# sam67_dmpac_wrap0_DMPAC_TOP_CFG_SLV_HTS_S_VBUSP register map
Vendor: Texas Instruments
Peripheral module from a debugger description file (folder J722S).
Registers are 32-bit, read-write, reset 0x0 unless marked. A register's access mark holds for its fields unless they carry their own. Offsets are as the file gives them; lines under a group give offsets from that group; [hi:lo] are bit positions; {n}, {i} and the like mark numbered series; 'fields as' and 'values as' point back to an identical list; <NAME> marks a mode.

## sam67_dmpac_wrap0_DMPAC_TOP_CFG_SLV_HTS_S_VBUSP (part 1 of 2)
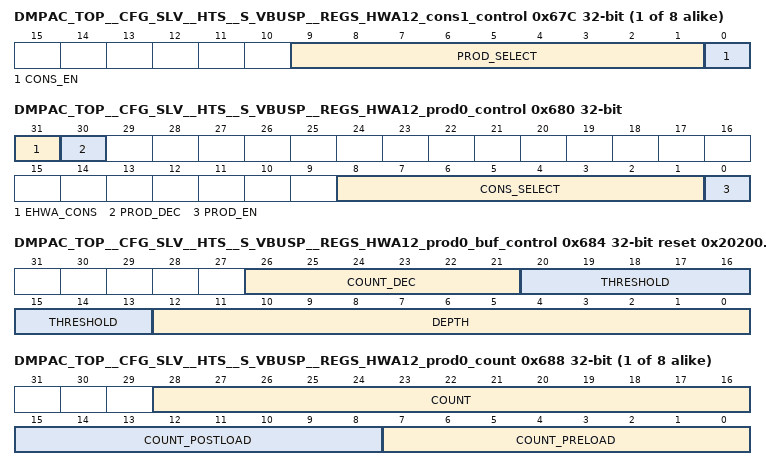
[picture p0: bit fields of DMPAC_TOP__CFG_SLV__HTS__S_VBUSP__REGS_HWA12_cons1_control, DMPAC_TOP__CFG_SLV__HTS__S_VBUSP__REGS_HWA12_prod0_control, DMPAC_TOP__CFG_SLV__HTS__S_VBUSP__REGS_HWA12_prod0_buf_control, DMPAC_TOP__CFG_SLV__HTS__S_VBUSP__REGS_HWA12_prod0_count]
{0x19C+0x68*i} DMPAC_TOP__CFG_SLV__HTS__S_VBUSP__REGS_HWA{i}_cons1_control (i=12..19) — Controlling consumer socket 1 for HWA{i}
  [9:1] PROD_SELECT — producer select for HWA{i} cons socket 1
  [0] CONS_EN — '1' -> Consumer socket 1 enable , '0' Disable
0x680 DMPAC_TOP__CFG_SLV__HTS__S_VBUSP__REGS_HWA12_prod0_control access per field — Controlling producer socket0 for HWA12
  [31] EHWA_CONS rw — '1' -> spare consumer is connected to external host consumer , '0' --> no external host consumer
  [30] PROD_DEC wo — writing '1' decrement prod count value
  [8:1] CONS_SELECT rw — consumer select for HWA12 prod socket 0. Used in decrementing count of producer buffer
  [0] PROD_EN rw — '1' -> Producer socket 0 enable , '0' Disable
{0x1A4+0x68*i} DMPAC_TOP__CFG_SLV__HTS__S_VBUSP__REGS_HWA{i}_prod0_buf_control reset 0x202000 (i=12..19) — Controlling producer socket0 buffer for HWA{i}
  [26:21] COUNT_DEC — Count decrement value for prod count
  [20:13] THRESHOLD — Count threshold to generate pend for consumer
  [12:0] DEPTH — Maximum number of producer buffer count
{0x1A8+0x68*i} DMPAC_TOP__CFG_SLV__HTS__S_VBUSP__REGS_HWA{i}_prod0_count access per field (i=12..19) — Defining count values for pre/post load for generating pend by HWA{i} prod0
  [28:16] COUNT ro — current count value
  [15:8] COUNT_POSTLOAD rw — count postload after producer max thread count reached
  [7:0] COUNT_PRELOAD rw — count preload after scheduler start/init
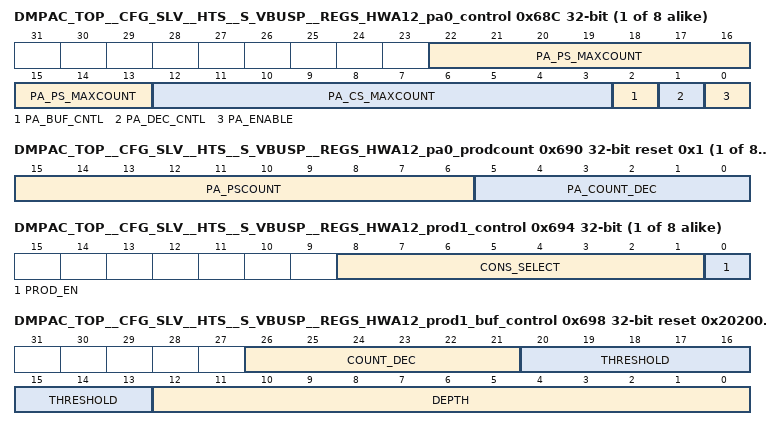
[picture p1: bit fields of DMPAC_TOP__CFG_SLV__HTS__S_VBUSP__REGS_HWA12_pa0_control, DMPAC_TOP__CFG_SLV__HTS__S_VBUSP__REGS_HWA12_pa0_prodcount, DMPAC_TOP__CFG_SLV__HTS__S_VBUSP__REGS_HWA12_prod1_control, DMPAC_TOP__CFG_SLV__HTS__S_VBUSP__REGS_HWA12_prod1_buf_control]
{0x1AC+0x68*i} DMPAC_TOP__CFG_SLV__HTS__S_VBUSP__REGS_HWA{i}_pa0_control (i=12..19) — control register to manage pattern adapter on HWA{i} prod socket0
  [22:13] PA_PS_MAXCOUNT — destination count for pattern adaptation (N), M --> N
  [12:3] PA_CS_MAXCOUNT — source count for pattern adaptation (M), M --> N
  [2] PA_BUF_CNTL — '1' -> Apply threshold, count_preload and count_postload on pattern adapter count (use this only when pa_enable='1') '0' -> Apply threshold, count_preload and count_postload on prod count (same behavior as if no pattern adapter. Note when pa_enable='1' and pa_buf_cntl='0' threshold is not used and ignored)
  [1] PA_DEC_CNTL — '1' -> post pattern adaptation, decrement ps count by count_dec , '0' -> post pattern adaptation, decrement ps count by pa_cs_maxcount
  [0] PA_ENABLE — '1' -> pa enable, '0' -> disable
{0x1B0+0x68*i} DMPAC_TOP__CFG_SLV__HTS__S_VBUSP__REGS_HWA{i}_pa0_prodcount access per field reset 0x1 (i=12..19) — count values for HWA{i} prod socket0
  [15:6] PA_PSCOUNT ro — current count value of pa prod count
  [5:0] PA_COUNT_DEC rw — Decrement count value of pa_prod_count after pattern adapter prod count reaches threshold
{0x1B4+0x68*i} DMPAC_TOP__CFG_SLV__HTS__S_VBUSP__REGS_HWA{i}_prod1_control (i=12..19) — Controlling producer socket1 for HWA{i}
  [8:1] CONS_SELECT — consumer select for HWA{i} prod socket 1. Used in decrementing count of producer buffer
  [0] PROD_EN — '1' -> Producer socket 0 enable , '0' Disable
{0x1B8+0x68*i} DMPAC_TOP__CFG_SLV__HTS__S_VBUSP__REGS_HWA{i}_prod1_buf_control reset 0x202000 (i=12..19) — Controlling producer socket1 buffer for HWA{i}
  fields as DMPAC_TOP__CFG_SLV__HTS__S_VBUSP__REGS_HWA12_prod0_buf_control
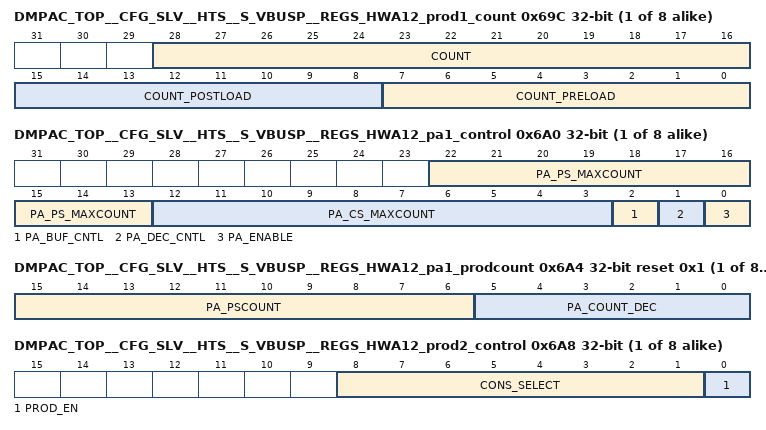
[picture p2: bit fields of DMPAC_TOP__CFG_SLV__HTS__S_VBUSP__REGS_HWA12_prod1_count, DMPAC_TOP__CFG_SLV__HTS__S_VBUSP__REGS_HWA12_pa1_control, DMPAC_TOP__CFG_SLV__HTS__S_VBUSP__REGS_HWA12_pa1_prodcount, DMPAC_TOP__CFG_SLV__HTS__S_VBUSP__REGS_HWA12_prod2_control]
{0x1BC+0x68*i} DMPAC_TOP__CFG_SLV__HTS__S_VBUSP__REGS_HWA{i}_prod1_count access per field (i=12..19) — Defining count values for pre/post load for generating pend by HWA{i} prod1
  fields as DMPAC_TOP__CFG_SLV__HTS__S_VBUSP__REGS_HWA12_prod0_count
{0x1C0+0x68*i} DMPAC_TOP__CFG_SLV__HTS__S_VBUSP__REGS_HWA{i}_pa1_control (i=12..19) — control register to manage pattern adapter on HWA{i} prod socket1
  fields as DMPAC_TOP__CFG_SLV__HTS__S_VBUSP__REGS_HWA12_pa0_control
{0x1C4+0x68*i} DMPAC_TOP__CFG_SLV__HTS__S_VBUSP__REGS_HWA{i}_pa1_prodcount access per field reset 0x1 (i=12..19) — count values for HWA{i} prod socket1
  fields as DMPAC_TOP__CFG_SLV__HTS__S_VBUSP__REGS_HWA12_pa0_prodcount
{0x1C8+0x68*i} DMPAC_TOP__CFG_SLV__HTS__S_VBUSP__REGS_HWA{i}_prod2_control (i=12..19) — Controlling producer socket2 for HWA{i}
  [8:1] CONS_SELECT — consumer select for HWA{i} prod socket 2. Used in decrementing count of producer buffer
  [0] PROD_EN — '1' -> Producer socket 0 enable , '0' Disable
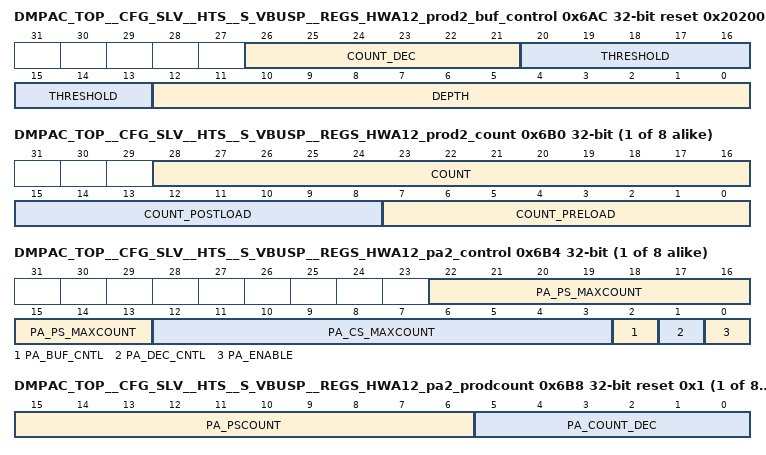
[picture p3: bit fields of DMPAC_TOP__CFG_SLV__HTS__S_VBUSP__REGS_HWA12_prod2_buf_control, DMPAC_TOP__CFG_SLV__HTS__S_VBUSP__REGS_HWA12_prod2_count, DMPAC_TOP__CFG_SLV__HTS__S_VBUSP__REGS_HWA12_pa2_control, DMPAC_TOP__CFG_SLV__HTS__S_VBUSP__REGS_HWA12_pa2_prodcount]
{0x1CC+0x68*i} DMPAC_TOP__CFG_SLV__HTS__S_VBUSP__REGS_HWA{i}_prod2_buf_control reset 0x202000 (i=12..19) — Controlling producer socket2 buffer for HWA{i}
  fields as DMPAC_TOP__CFG_SLV__HTS__S_VBUSP__REGS_HWA12_prod0_buf_control
{0x1D0+0x68*i} DMPAC_TOP__CFG_SLV__HTS__S_VBUSP__REGS_HWA{i}_prod2_count access per field (i=12..19) — Defining count values for pre/post load for generating pend by HWA{i} prod2
  fields as DMPAC_TOP__CFG_SLV__HTS__S_VBUSP__REGS_HWA12_prod0_count
{0x1D4+0x68*i} DMPAC_TOP__CFG_SLV__HTS__S_VBUSP__REGS_HWA{i}_pa2_control (i=12..19) — control register to manage pattern adapter on HWA{i} prod socket2
  fields as DMPAC_TOP__CFG_SLV__HTS__S_VBUSP__REGS_HWA12_pa0_control
{0x1D8+0x68*i} DMPAC_TOP__CFG_SLV__HTS__S_VBUSP__REGS_HWA{i}_pa2_prodcount access per field reset 0x1 (i=12..19) — count values for HWA{i} prod socket2
  fields as DMPAC_TOP__CFG_SLV__HTS__S_VBUSP__REGS_HWA12_pa0_prodcount
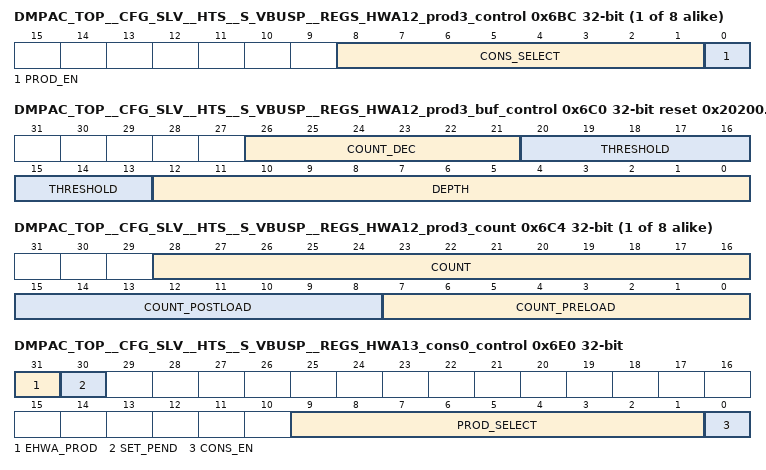
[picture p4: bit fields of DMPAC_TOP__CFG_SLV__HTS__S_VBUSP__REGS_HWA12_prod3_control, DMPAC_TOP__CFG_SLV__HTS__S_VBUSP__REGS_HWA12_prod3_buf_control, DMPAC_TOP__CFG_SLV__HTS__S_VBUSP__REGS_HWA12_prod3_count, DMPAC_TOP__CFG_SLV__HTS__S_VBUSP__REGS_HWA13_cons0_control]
{0x1DC+0x68*i} DMPAC_TOP__CFG_SLV__HTS__S_VBUSP__REGS_HWA{i}_prod3_control (i=12..19) — Controlling producer socket3 for HWA{i}
  [8:1] CONS_SELECT — consumer select for HWA{i} prod socket 3. Used in decrementing count of producer buffer
  [0] PROD_EN — '1' -> Producer socket 0 enable , '0' Disable
{0x1E0+0x68*i} DMPAC_TOP__CFG_SLV__HTS__S_VBUSP__REGS_HWA{i}_prod3_buf_control reset 0x202000 (i=12..19) — Controlling producer socket3 buffer for HWA{i}
  fields as DMPAC_TOP__CFG_SLV__HTS__S_VBUSP__REGS_HWA12_prod0_buf_control
{0x1E4+0x68*i} DMPAC_TOP__CFG_SLV__HTS__S_VBUSP__REGS_HWA{i}_prod3_count access per field (i=12..19) — Defining count values for pre/post load for generating pend by HWA{i} prod3
  fields as DMPAC_TOP__CFG_SLV__HTS__S_VBUSP__REGS_HWA12_prod0_count
0x6E0 DMPAC_TOP__CFG_SLV__HTS__S_VBUSP__REGS_HWA13_cons0_control access per field — Controlling consumer socket 0 for HWA13
  [31] EHWA_PROD rw — '1' -> spare consumer is connected to external host producer , '0' --> no external host producer
  [30] SET_PEND wo — writing '1' sets pend on consumer socket
  [9:1] PROD_SELECT rw — producer select for HWA13 cons socket 0
  [0] CONS_EN rw — '1' -> Consumer socket 0 enable , '0' Disable
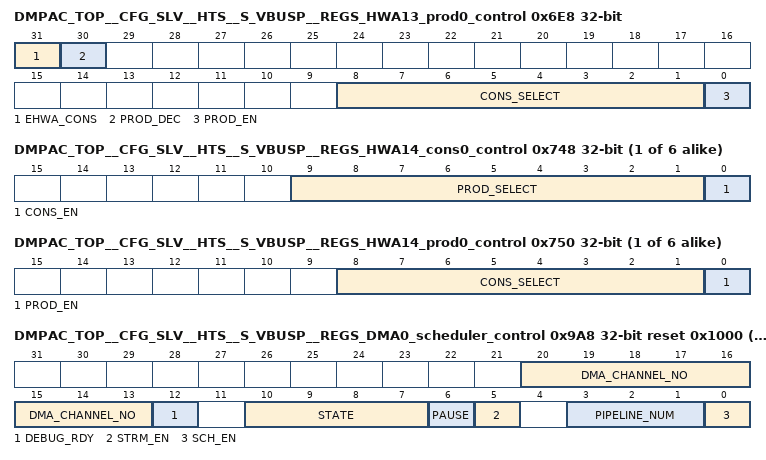
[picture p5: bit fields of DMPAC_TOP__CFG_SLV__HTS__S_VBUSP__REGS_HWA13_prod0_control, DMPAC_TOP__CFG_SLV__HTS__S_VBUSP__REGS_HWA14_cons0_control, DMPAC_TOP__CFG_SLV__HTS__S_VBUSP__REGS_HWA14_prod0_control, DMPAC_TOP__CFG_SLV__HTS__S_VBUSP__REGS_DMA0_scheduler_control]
0x6E8 DMPAC_TOP__CFG_SLV__HTS__S_VBUSP__REGS_HWA13_prod0_control access per field — Controlling producer socket0 for HWA13
  [31] EHWA_CONS rw — '1' -> spare consumer is connected to external host consumer , '0' --> no external host consumer
  [30] PROD_DEC wo — writing '1' decrement prod count value
  [8:1] CONS_SELECT rw — consumer select for HWA13 prod socket 0. Used in decrementing count of producer buffer
  [0] PROD_EN rw — '1' -> Producer socket 0 enable , '0' Disable
{0x198+0x68*i} DMPAC_TOP__CFG_SLV__HTS__S_VBUSP__REGS_HWA{i}_cons0_control (i=14..19) — Controlling consumer socket 0 for HWA{i}
  [9:1] PROD_SELECT — producer select for HWA{i} cons socket 0
  [0] CONS_EN — '1' -> Consumer socket 0 enable , '0' Disable
{0x1A0+0x68*i} DMPAC_TOP__CFG_SLV__HTS__S_VBUSP__REGS_HWA{i}_prod0_control (i=14..19) — Controlling producer socket0 for HWA{i}
  [8:1] CONS_SELECT — consumer select for HWA{i} prod socket 0. Used in decrementing count of producer buffer
  [0] PROD_EN — '1' -> Producer socket 0 enable , '0' Disable
{0x9A8+0x1C*i} DMPAC_TOP__CFG_SLV__HTS__S_VBUSP__REGS_DMA{i}_scheduler_control access per field reset 0x1000 (i=0..4) — Scheduler Control Register
  [20:13] DMA_CHANNEL_NO rw — DMA channel number for thread scheduler for DMA{i}
  [12] DEBUG_RDY rw — '0' -> DMA{i} Scheduler resources must not be read during halted state. '1'-> DMA{i} Scheduler resources are readable during halted state
  [10:7] STATE ro — Current state of DMA{i} Scheduler
  [6] PAUSE rw — '1' -> pause/suspend scheduler , '0' -> resume scheduler
  [5] STRM_EN rw — '1' -> Streaming input enable, '0' No streaming input
  [3:1] PIPELINE_NUM rw — Pipeline Number of DMA{i} Scheduler
  [0] SCH_EN rw — scheduler enable; write '1' to enable scheduler
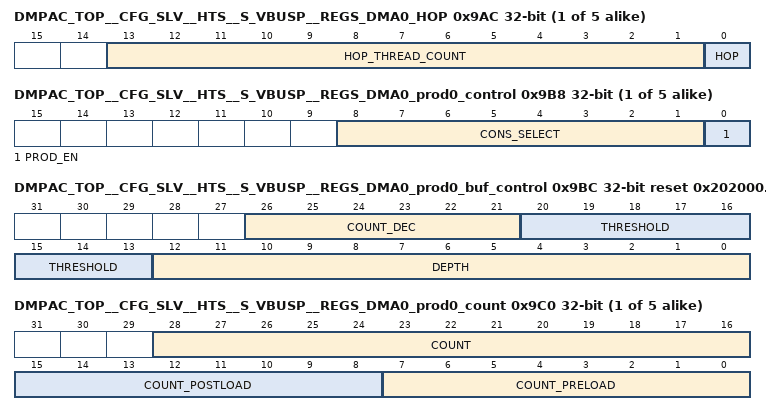
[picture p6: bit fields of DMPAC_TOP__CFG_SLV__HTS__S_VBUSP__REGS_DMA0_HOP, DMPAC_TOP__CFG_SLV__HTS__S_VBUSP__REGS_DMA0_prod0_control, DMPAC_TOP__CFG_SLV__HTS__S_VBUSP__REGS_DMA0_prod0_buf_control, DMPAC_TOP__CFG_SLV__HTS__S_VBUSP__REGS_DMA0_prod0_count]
{0x9AC+0x1C*i} DMPAC_TOP__CFG_SLV__HTS__S_VBUSP__REGS_DMA{i}_HOP (i=0..4) — Scheduler HOP Control Register. Help in detecting eop within scheduler. Once configured, it counts task/channel starts and stops issuing further starts. Specifically useful for Head of pipe dma scheduler .
  [13:1] HOP_THREAD_COUNT — Number of Task count for Head of pipe
  [0] HOP — '1' -> Head of Pipe producer Sch , '0' -> No hop
{0x9B8+0x1C*i} DMPAC_TOP__CFG_SLV__HTS__S_VBUSP__REGS_DMA{i}_prod0_control (i=0..4) — Controlling producer socket0 for DMA{i}
  [8:1] CONS_SELECT — consumer select for DMA{i} prod socket 0. Used in decrementing count of producer buffer
  [0] PROD_EN — '1' -> Producer socket 0 enable , '0' Disable
{0x9BC+0x1C*i} DMPAC_TOP__CFG_SLV__HTS__S_VBUSP__REGS_DMA{i}_prod0_buf_control reset 0x202000 (i=0..4) — Controlling producer socket0 buffer for DMA{i}
  fields as DMPAC_TOP__CFG_SLV__HTS__S_VBUSP__REGS_HWA12_prod0_buf_control
{0x9C0+0x1C*i} DMPAC_TOP__CFG_SLV__HTS__S_VBUSP__REGS_DMA{i}_prod0_count access per field (i=0..4) — Defining count values for pre/post load for generating pend by DMA{i} prod0
  fields as DMPAC_TOP__CFG_SLV__HTS__S_VBUSP__REGS_HWA12_prod0_count
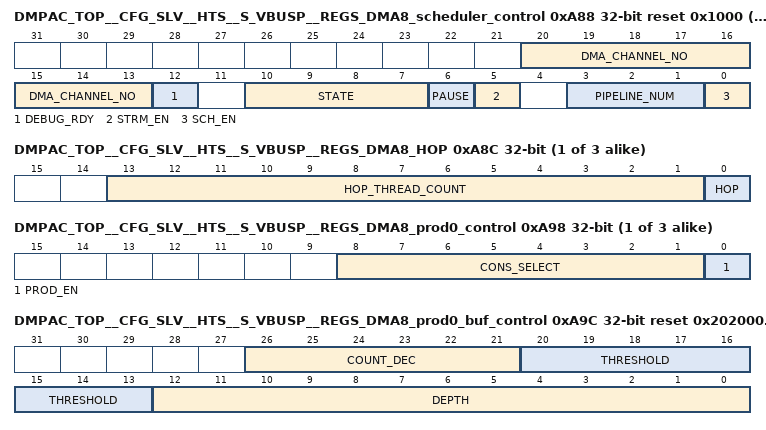
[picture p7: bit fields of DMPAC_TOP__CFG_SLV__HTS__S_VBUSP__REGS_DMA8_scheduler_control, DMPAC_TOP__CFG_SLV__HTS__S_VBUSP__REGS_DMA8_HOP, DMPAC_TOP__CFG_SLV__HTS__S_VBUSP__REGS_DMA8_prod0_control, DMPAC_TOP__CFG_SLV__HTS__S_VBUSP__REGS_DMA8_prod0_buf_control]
{0x968+0x24*i} DMPAC_TOP__CFG_SLV__HTS__S_VBUSP__REGS_DMA{i}_scheduler_control access per field reset 0x1000 (i=8..10) — Scheduler Control Register
  fields as DMPAC_TOP__CFG_SLV__HTS__S_VBUSP__REGS_DMA0_scheduler_control
{0x96C+0x24*i} DMPAC_TOP__CFG_SLV__HTS__S_VBUSP__REGS_DMA{i}_HOP (i=8..10) — Scheduler HOP Control Register. Help in detecting eop within scheduler. Once configured, it counts task/channel starts and stops issuing further starts. Specifically useful for Head of pipe dma scheduler .
  fields as DMPAC_TOP__CFG_SLV__HTS__S_VBUSP__REGS_DMA0_HOP
{0x978+0x24*i} DMPAC_TOP__CFG_SLV__HTS__S_VBUSP__REGS_DMA{i}_prod0_control (i=8..10) — Controlling producer socket0 for DMA{i}
  fields as DMPAC_TOP__CFG_SLV__HTS__S_VBUSP__REGS_DMA0_prod0_control
{0x97C+0x24*i} DMPAC_TOP__CFG_SLV__HTS__S_VBUSP__REGS_DMA{i}_prod0_buf_control reset 0x202000 (i=8..10) — Controlling producer socket0 buffer for DMA{i}
  fields as DMPAC_TOP__CFG_SLV__HTS__S_VBUSP__REGS_HWA12_prod0_buf_control
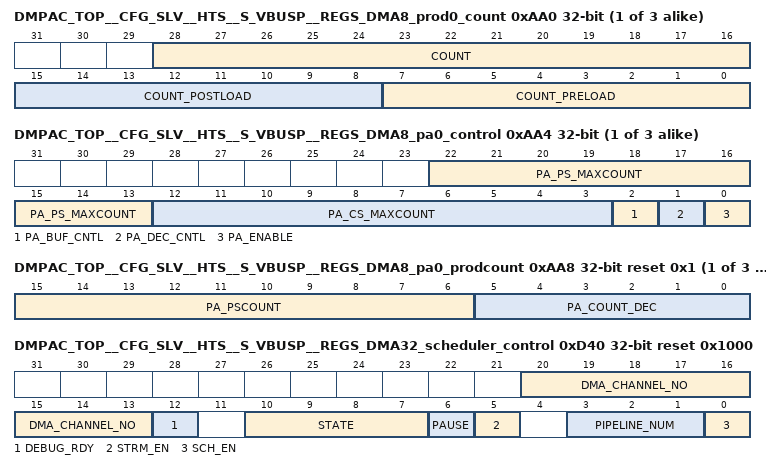
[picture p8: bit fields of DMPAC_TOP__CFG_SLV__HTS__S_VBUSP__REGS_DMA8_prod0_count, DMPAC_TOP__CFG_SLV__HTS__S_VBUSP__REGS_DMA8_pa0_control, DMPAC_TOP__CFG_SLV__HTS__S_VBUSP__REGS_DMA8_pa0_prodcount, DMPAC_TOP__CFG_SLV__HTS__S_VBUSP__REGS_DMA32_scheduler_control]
{0x980+0x24*i} DMPAC_TOP__CFG_SLV__HTS__S_VBUSP__REGS_DMA{i}_prod0_count access per field (i=8..10) — Defining count values for pre/post load for generating pend by DMA{i} prod0
  fields as DMPAC_TOP__CFG_SLV__HTS__S_VBUSP__REGS_HWA12_prod0_count
{0x984+0x24*i} DMPAC_TOP__CFG_SLV__HTS__S_VBUSP__REGS_DMA{i}_pa0_control (i=8..10) — control register to manage pattern adapter on DMA{i} prod socket0
  fields as DMPAC_TOP__CFG_SLV__HTS__S_VBUSP__REGS_HWA12_pa0_control
{0x988+0x24*i} DMPAC_TOP__CFG_SLV__HTS__S_VBUSP__REGS_DMA{i}_pa0_prodcount access per field reset 0x1 (i=8..10) — count values for HWA{i} prod socket0
  fields as DMPAC_TOP__CFG_SLV__HTS__S_VBUSP__REGS_HWA12_pa0_prodcount
0xD40 DMPAC_TOP__CFG_SLV__HTS__S_VBUSP__REGS_DMA32_scheduler_control access per field reset 0x1000 — Scheduler Control Register
  [20:13] DMA_CHANNEL_NO rw — DMA channel number for thread scheduler for DMA32
  [12] DEBUG_RDY rw — '0' -> DMA32 Scheduler resources must not be read during halted state. '1'-> DMA32 Scheduler resources are readable during halted state
  [10:7] STATE ro — Current state of DMA32 Scheduler
  [6] PAUSE rw — '1' -> pause/suspend scheduler , '0' -> resume scheduler
  [5] STRM_EN rw — '1' -> Streaming input enable, '0' No streaming input
  [3:1] PIPELINE_NUM rw — Pipeline Number of DMA32 Scheduler
  [0] SCH_EN rw — scheduler enable; write '1' to enable scheduler
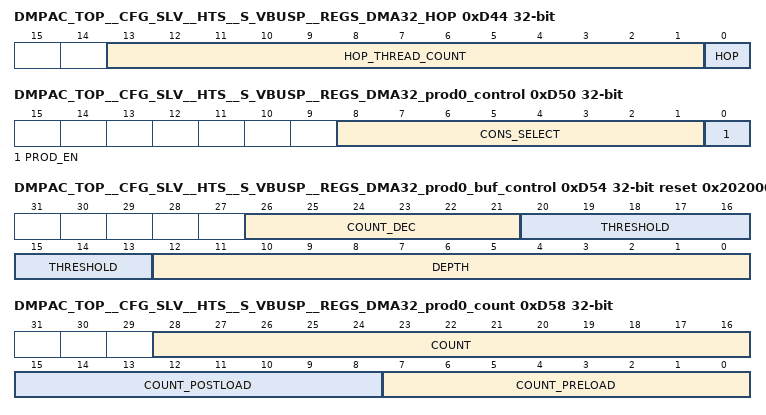
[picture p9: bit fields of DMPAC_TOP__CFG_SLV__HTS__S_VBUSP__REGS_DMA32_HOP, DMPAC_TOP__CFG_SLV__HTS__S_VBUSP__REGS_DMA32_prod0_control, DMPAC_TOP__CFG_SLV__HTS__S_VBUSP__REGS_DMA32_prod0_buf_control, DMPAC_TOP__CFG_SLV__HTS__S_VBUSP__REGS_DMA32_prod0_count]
0xD44 DMPAC_TOP__CFG_SLV__HTS__S_VBUSP__REGS_DMA32_HOP — Scheduler HOP Control Register. Help in detecting eop within scheduler. Once configured, it counts task/channel starts and stops issuing further starts. Specifically useful for Head of pipe dma scheduler .
  fields as DMPAC_TOP__CFG_SLV__HTS__S_VBUSP__REGS_DMA0_HOP
0xD50 DMPAC_TOP__CFG_SLV__HTS__S_VBUSP__REGS_DMA32_prod0_control — Controlling producer socket0 for DMA32
  [8:1] CONS_SELECT — consumer select for DMA32 prod socket 0. Used in decrementing count of producer buffer
  [0] PROD_EN — '1' -> Producer socket 0 enable , '0' Disable
0xD54 DMPAC_TOP__CFG_SLV__HTS__S_VBUSP__REGS_DMA32_prod0_buf_control reset 0x202000 — Controlling producer socket0 buffer for DMA32
  fields as DMPAC_TOP__CFG_SLV__HTS__S_VBUSP__REGS_HWA12_prod0_buf_control
0xD58 DMPAC_TOP__CFG_SLV__HTS__S_VBUSP__REGS_DMA32_prod0_count access per field — Defining count values for pre/post load for generating pend by DMA32 prod0
  fields as DMPAC_TOP__CFG_SLV__HTS__S_VBUSP__REGS_HWA12_prod0_count
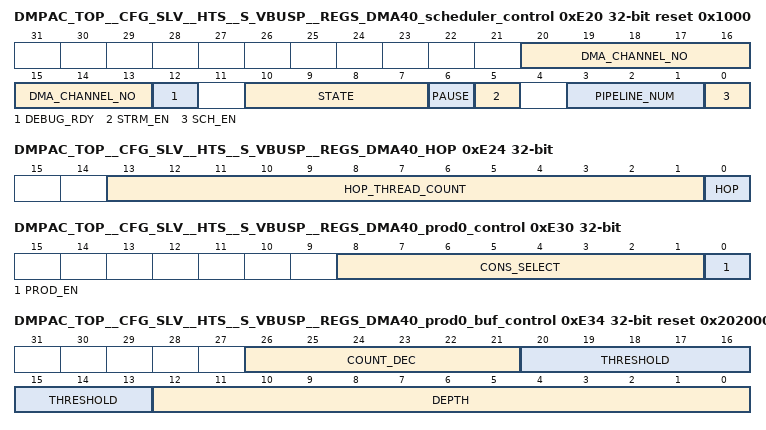
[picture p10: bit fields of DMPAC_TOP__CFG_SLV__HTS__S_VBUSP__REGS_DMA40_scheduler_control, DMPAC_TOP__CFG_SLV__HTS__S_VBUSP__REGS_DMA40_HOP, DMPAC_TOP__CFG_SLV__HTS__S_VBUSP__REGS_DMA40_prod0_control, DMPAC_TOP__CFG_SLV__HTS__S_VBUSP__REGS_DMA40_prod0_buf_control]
0xE20 DMPAC_TOP__CFG_SLV__HTS__S_VBUSP__REGS_DMA40_scheduler_control access per field reset 0x1000 — Scheduler Control Register
  [20:13] DMA_CHANNEL_NO rw — DMA channel number for thread scheduler for DMA40
  [12] DEBUG_RDY rw — '0' -> DMA40 Scheduler resources must not be read during halted state. '1'-> DMA40 Scheduler resources are readable during halted state
  [10:7] STATE ro — Current state of DMA40 Scheduler
  [6] PAUSE rw — '1' -> pause/suspend scheduler , '0' -> resume scheduler
  [5] STRM_EN rw — '1' -> Streaming input enable, '0' No streaming input
  [3:1] PIPELINE_NUM rw — Pipeline Number of DMA40 Scheduler
  [0] SCH_EN rw — scheduler enable; write '1' to enable scheduler
0xE24 DMPAC_TOP__CFG_SLV__HTS__S_VBUSP__REGS_DMA40_HOP — Scheduler HOP Control Register. Help in detecting eop within scheduler. Once configured, it counts task/channel starts and stops issuing further starts. Specifically useful for Head of pipe dma scheduler .
  fields as DMPAC_TOP__CFG_SLV__HTS__S_VBUSP__REGS_DMA0_HOP
0xE30 DMPAC_TOP__CFG_SLV__HTS__S_VBUSP__REGS_DMA40_prod0_control — Controlling producer socket0 for DMA40
  [8:1] CONS_SELECT — consumer select for DMA40 prod socket 0. Used in decrementing count of producer buffer
  [0] PROD_EN — '1' -> Producer socket 0 enable , '0' Disable
0xE34 DMPAC_TOP__CFG_SLV__HTS__S_VBUSP__REGS_DMA40_prod0_buf_control reset 0x202000 — Controlling producer socket0 buffer for DMA40
  fields as DMPAC_TOP__CFG_SLV__HTS__S_VBUSP__REGS_HWA12_prod0_buf_control
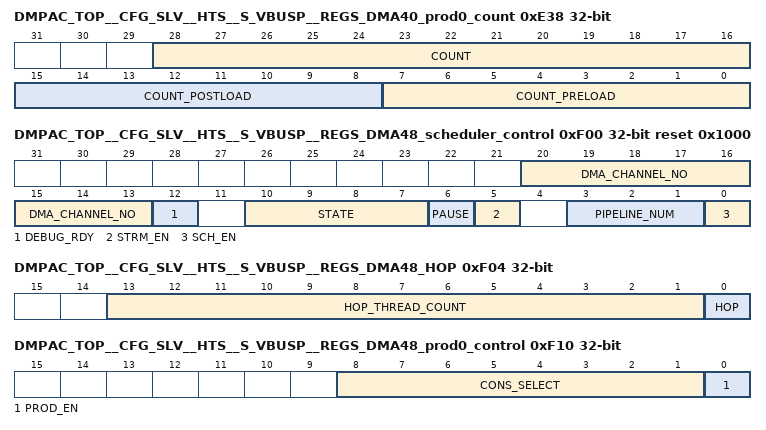
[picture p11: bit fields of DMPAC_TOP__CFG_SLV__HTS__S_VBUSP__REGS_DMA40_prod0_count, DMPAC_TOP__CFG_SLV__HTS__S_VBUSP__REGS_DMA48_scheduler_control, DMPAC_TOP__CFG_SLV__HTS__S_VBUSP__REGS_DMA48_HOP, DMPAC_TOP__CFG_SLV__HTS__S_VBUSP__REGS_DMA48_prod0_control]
0xE38 DMPAC_TOP__CFG_SLV__HTS__S_VBUSP__REGS_DMA40_prod0_count access per field — Defining count values for pre/post load for generating pend by DMA40 prod0
  fields as DMPAC_TOP__CFG_SLV__HTS__S_VBUSP__REGS_HWA12_prod0_count
0xF00 DMPAC_TOP__CFG_SLV__HTS__S_VBUSP__REGS_DMA48_scheduler_control access per field reset 0x1000 — Scheduler Control Register
  [20:13] DMA_CHANNEL_NO rw — DMA channel number for thread scheduler for DMA48
  [12] DEBUG_RDY rw — '0' -> DMA48 Scheduler resources must not be read during halted state. '1'-> DMA48 Scheduler resources are readable during halted state
  [10:7] STATE ro — Current state of DMA48 Scheduler
  [6] PAUSE rw — '1' -> pause/suspend scheduler , '0' -> resume scheduler
  [5] STRM_EN rw — '1' -> Streaming input enable, '0' No streaming input
  [3:1] PIPELINE_NUM rw — Pipeline Number of DMA48 Scheduler
  [0] SCH_EN rw — scheduler enable; write '1' to enable scheduler
0xF04 DMPAC_TOP__CFG_SLV__HTS__S_VBUSP__REGS_DMA48_HOP — Scheduler HOP Control Register. Help in detecting eop within scheduler. Once configured, it counts task/channel starts and stops issuing further starts. Specifically useful for Head of pipe dma scheduler .
  fields as DMPAC_TOP__CFG_SLV__HTS__S_VBUSP__REGS_DMA0_HOP
0xF10 DMPAC_TOP__CFG_SLV__HTS__S_VBUSP__REGS_DMA48_prod0_control — Controlling producer socket0 for DMA48
  [8:1] CONS_SELECT — consumer select for DMA48 prod socket 0. Used in decrementing count of producer buffer
  [0] PROD_EN — '1' -> Producer socket 0 enable , '0' Disable
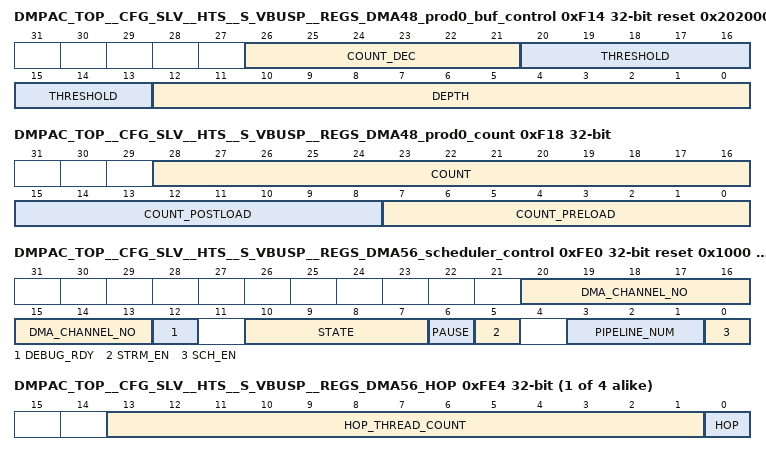
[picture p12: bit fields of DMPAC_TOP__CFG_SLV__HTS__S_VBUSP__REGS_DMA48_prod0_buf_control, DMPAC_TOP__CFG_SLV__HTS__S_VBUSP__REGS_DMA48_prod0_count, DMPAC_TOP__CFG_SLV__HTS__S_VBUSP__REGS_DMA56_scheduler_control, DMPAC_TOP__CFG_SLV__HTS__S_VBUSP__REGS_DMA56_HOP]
0xF14 DMPAC_TOP__CFG_SLV__HTS__S_VBUSP__REGS_DMA48_prod0_buf_control reset 0x202000 — Controlling producer socket0 buffer for DMA48
  fields as DMPAC_TOP__CFG_SLV__HTS__S_VBUSP__REGS_HWA12_prod0_buf_control
0xF18 DMPAC_TOP__CFG_SLV__HTS__S_VBUSP__REGS_DMA48_prod0_count access per field — Defining count values for pre/post load for generating pend by DMA48 prod0
  fields as DMPAC_TOP__CFG_SLV__HTS__S_VBUSP__REGS_HWA12_prod0_count
{0x9C0+0x1C*i} DMPAC_TOP__CFG_SLV__HTS__S_VBUSP__REGS_DMA{i}_scheduler_control access per field reset 0x1000 (i=56..59) — Scheduler Control Register
  fields as DMPAC_TOP__CFG_SLV__HTS__S_VBUSP__REGS_DMA0_scheduler_control
{0x9C4+0x1C*i} DMPAC_TOP__CFG_SLV__HTS__S_VBUSP__REGS_DMA{i}_HOP (i=56..59) — Scheduler HOP Control Register. Help in detecting eop within scheduler. Once configured, it counts task/channel starts and stops issuing further starts. Specifically useful for Head of pipe dma scheduler .
  fields as DMPAC_TOP__CFG_SLV__HTS__S_VBUSP__REGS_DMA0_HOP
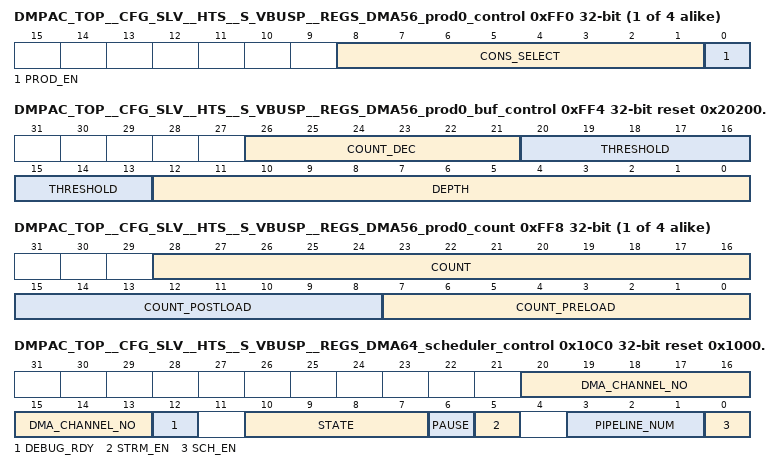
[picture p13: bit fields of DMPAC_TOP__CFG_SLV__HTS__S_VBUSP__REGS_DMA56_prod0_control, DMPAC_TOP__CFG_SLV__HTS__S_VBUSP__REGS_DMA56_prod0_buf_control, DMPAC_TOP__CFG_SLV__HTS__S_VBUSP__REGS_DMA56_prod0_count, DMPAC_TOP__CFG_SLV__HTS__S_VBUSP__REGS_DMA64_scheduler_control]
{0x9D0+0x1C*i} DMPAC_TOP__CFG_SLV__HTS__S_VBUSP__REGS_DMA{i}_prod0_control (i=56..59) — Controlling producer socket0 for DMA{i}
  fields as DMPAC_TOP__CFG_SLV__HTS__S_VBUSP__REGS_DMA0_prod0_control
{0x9D4+0x1C*i} DMPAC_TOP__CFG_SLV__HTS__S_VBUSP__REGS_DMA{i}_prod0_buf_control reset 0x202000 (i=56..59) — Controlling producer socket0 buffer for DMA{i}
  fields as DMPAC_TOP__CFG_SLV__HTS__S_VBUSP__REGS_HWA12_prod0_buf_control
{0x9D8+0x1C*i} DMPAC_TOP__CFG_SLV__HTS__S_VBUSP__REGS_DMA{i}_prod0_count access per field (i=56..59) — Defining count values for pre/post load for generating pend by DMA{i} prod0
  fields as DMPAC_TOP__CFG_SLV__HTS__S_VBUSP__REGS_HWA12_prod0_count
{0x9C0+0x1C*i} DMPAC_TOP__CFG_SLV__HTS__S_VBUSP__REGS_DMA{i}_scheduler_control access per field reset 0x1000 (i=64..67) — Scheduler Control Register
  fields as DMPAC_TOP__CFG_SLV__HTS__S_VBUSP__REGS_DMA0_scheduler_control
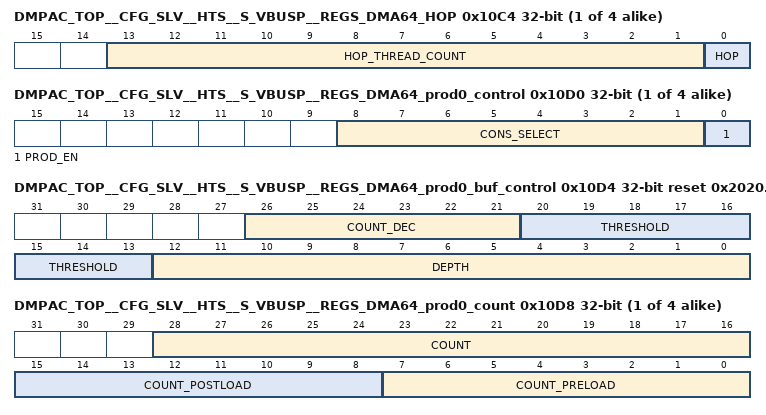
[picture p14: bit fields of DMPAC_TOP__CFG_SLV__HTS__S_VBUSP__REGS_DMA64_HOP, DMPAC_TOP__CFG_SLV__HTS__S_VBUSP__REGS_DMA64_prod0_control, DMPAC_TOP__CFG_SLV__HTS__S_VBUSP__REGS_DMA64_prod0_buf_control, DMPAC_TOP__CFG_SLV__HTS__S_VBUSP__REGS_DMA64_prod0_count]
{0x9C4+0x1C*i} DMPAC_TOP__CFG_SLV__HTS__S_VBUSP__REGS_DMA{i}_HOP (i=64..67) — Scheduler HOP Control Register. Help in detecting eop within scheduler. Once configured, it counts task/channel starts and stops issuing further starts. Specifically useful for Head of pipe dma scheduler .
  fields as DMPAC_TOP__CFG_SLV__HTS__S_VBUSP__REGS_DMA0_HOP
{0x9D0+0x1C*i} DMPAC_TOP__CFG_SLV__HTS__S_VBUSP__REGS_DMA{i}_prod0_control (i=64..67) — Controlling producer socket0 for DMA{i}
  fields as DMPAC_TOP__CFG_SLV__HTS__S_VBUSP__REGS_DMA0_prod0_control
{0x9D4+0x1C*i} DMPAC_TOP__CFG_SLV__HTS__S_VBUSP__REGS_DMA{i}_prod0_buf_control reset 0x202000 (i=64..67) — Controlling producer socket0 buffer for DMA{i}
  fields as DMPAC_TOP__CFG_SLV__HTS__S_VBUSP__REGS_HWA12_prod0_buf_control
{0x9D8+0x1C*i} DMPAC_TOP__CFG_SLV__HTS__S_VBUSP__REGS_DMA{i}_prod0_count access per field (i=64..67) — Defining count values for pre/post load for generating pend by DMA{i} prod0
  fields as DMPAC_TOP__CFG_SLV__HTS__S_VBUSP__REGS_HWA12_prod0_count
{0xEF4+0x14*i} DMPAC_TOP__CFG_SLV__HTS__S_VBUSP__REGS_DMA{i}_scheduler_control access per field reset 0x1000 (i=240..245) — Scheduler Control Register
  fields as DMPAC_TOP__CFG_SLV__HTS__S_VBUSP__REGS_DMA0_scheduler_control
{0xF04+0x14*i} DMPAC_TOP__CFG_SLV__HTS__S_VBUSP__REGS_DMA{i}_cons0_control (i=240..245) — Controlling consumer socket 0 for DMA{i}
  [9:1] PROD_SELECT — producer select for DMA{i} cons socket 0
  [0] CONS_EN — '1' -> Consumer socket 0 enable , '0' Disable
{0xE2C+0x14*i} DMPAC_TOP__CFG_SLV__HTS__S_VBUSP__REGS_DMA{i}_scheduler_control access per field reset 0x1000 (i=256..261) — Scheduler Control Register
  fields as DMPAC_TOP__CFG_SLV__HTS__S_VBUSP__REGS_DMA0_scheduler_control
{0xE3C+0x14*i} DMPAC_TOP__CFG_SLV__HTS__S_VBUSP__REGS_DMA{i}_cons0_control (i=256..261) — Controlling consumer socket 0 for DMA{i}
  fields as DMPAC_TOP__CFG_SLV__HTS__S_VBUSP__REGS_DMA240_cons0_control
{0xD64+0x14*i} DMPAC_TOP__CFG_SLV__HTS__S_VBUSP__REGS_DMA{i}_scheduler_control access per field reset 0x1000 (i=272..275) — Scheduler Control Register
  fields as DMPAC_TOP__CFG_SLV__HTS__S_VBUSP__REGS_DMA0_scheduler_control
{0xD74+0x14*i} DMPAC_TOP__CFG_SLV__HTS__S_VBUSP__REGS_DMA{i}_cons0_control (i=272..275) — Controlling consumer socket 0 for DMA{i}
  fields as DMPAC_TOP__CFG_SLV__HTS__S_VBUSP__REGS_DMA240_cons0_control
{0xC74+0x14*i} DMPAC_TOP__CFG_SLV__HTS__S_VBUSP__REGS_DMA{i}_scheduler_control access per field reset 0x1000 (i=288..291) — Scheduler Control Register
  fields as DMPAC_TOP__CFG_SLV__HTS__S_VBUSP__REGS_DMA0_scheduler_control
{0xC84+0x14*i} DMPAC_TOP__CFG_SLV__HTS__S_VBUSP__REGS_DMA{i}_cons0_control (i=288..291) — Controlling consumer socket 0 for DMA{i}
  fields as DMPAC_TOP__CFG_SLV__HTS__S_VBUSP__REGS_DMA240_cons0_control
{0xB84+0x14*i} DMPAC_TOP__CFG_SLV__HTS__S_VBUSP__REGS_DMA{i}_scheduler_control access per field reset 0x1000 (i=304..313) — Scheduler Control Register
  fields as DMPAC_TOP__CFG_SLV__HTS__S_VBUSP__REGS_DMA0_scheduler_control
{0xB94+0x14*i} DMPAC_TOP__CFG_SLV__HTS__S_VBUSP__REGS_DMA{i}_cons0_control (i=304..313) — Controlling consumer socket 0 for DMA{i}
  fields as DMPAC_TOP__CFG_SLV__HTS__S_VBUSP__REGS_DMA240_cons0_control
0x240C DMPAC_TOP__CFG_SLV__HTS__S_VBUSP__REGS_DMA336_scheduler_control access per field reset 0x1000 — Scheduler Control Register
  [20:13] DMA_CHANNEL_NO rw — DMA channel number for thread scheduler for DMA336
  [12] DEBUG_RDY rw — '0' -> DMA336 Scheduler resources must not be read during halted state. '1'-> DMA336 Scheduler resources are readable during halted state
  [10:7] STATE ro — Current state of DMA336 Scheduler
  [6] PAUSE rw — '1' -> pause/suspend scheduler , '0' -> resume scheduler
  [5] STRM_EN rw — '1' -> Streaming input enable, '0' No streaming input
  [3:1] PIPELINE_NUM rw — Pipeline Number of DMA336 Scheduler
  [0] SCH_EN rw — scheduler enable; write '1' to enable scheduler
0x241C DMPAC_TOP__CFG_SLV__HTS__S_VBUSP__REGS_DMA336_cons0_control — Controlling consumer socket 0 for DMA336
  [9:1] PROD_SELECT — producer select for DMA336 cons socket 0
  [0] CONS_EN — '1' -> Consumer socket 0 enable , '0' Disable
{0x8A0+0x14*i} DMPAC_TOP__CFG_SLV__HTS__S_VBUSP__REGS_DMA{i}_scheduler_control access per field reset 0x1000 (i=352..355) — Scheduler Control Register
  fields as DMPAC_TOP__CFG_SLV__HTS__S_VBUSP__REGS_DMA0_scheduler_control
{0x8B0+0x14*i} DMPAC_TOP__CFG_SLV__HTS__S_VBUSP__REGS_DMA{i}_cons0_control (i=352..355) — Controlling consumer socket 0 for DMA{i}
  fields as DMPAC_TOP__CFG_SLV__HTS__S_VBUSP__REGS_DMA240_cons0_control
{0x7B0+0x14*i} DMPAC_TOP__CFG_SLV__HTS__S_VBUSP__REGS_DMA{i}_scheduler_control access per field reset 0x1000 (i=368..371) — Scheduler Control Register
  fields as DMPAC_TOP__CFG_SLV__HTS__S_VBUSP__REGS_DMA0_scheduler_control
{0x7C0+0x14*i} DMPAC_TOP__CFG_SLV__HTS__S_VBUSP__REGS_DMA{i}_cons0_control (i=368..371) — Controlling consumer socket 0 for DMA{i}
  fields as DMPAC_TOP__CFG_SLV__HTS__S_VBUSP__REGS_DMA240_cons0_control
0x2650 DMPAC_TOP__CFG_SLV__HTS__S_VBUSP__REGS_pipe_dbg_cntl access per field — Pipeline Debug Control register is used by debug software to control pipeline debug behavior
  [19:17] DEBUG_STATE ro — Current state of Debug activity
  [16] ABORT_DEBUG wo — '1' -> Abort Debug activity on debug enabled pipelines, '0' no impact
  [6] PIPE_DBG_DIS_6 rw — '1' -> Pipeline6 doesn't respond to debug events, '0' Pipeline5 respond to debug events
  [n] PIPE_DBG_DIS_{n} rw (n=0..5) — '1' -> Pipeline{n} doesn't respond to debug events, '0' Pipeline{n} respond to debug events
0x2654 DMPAC_TOP__CFG_SLV__HTS__S_VBUSP__REGS_dbg_cap ro reset 0xD00020 — Debug Capability register is used by debug software to determine which optional debug modules are present and how many instances of each module exist.
  [30] DBG_INT_STEP_SUP — Indicates that debug execution control can determine if single step blocks or allows interrupts. b0 No step/interrupt control b1 Step interrupt control via DBG_INT_STEP_IN
  [29] DBG_WP_DATA_SUP — Indicates if the WP resources has corresponding data qualification. b0 - Not supported. b1 - Data qualifiers are supported.
  [28] DBG_OWN_SUP — Indicates if the HWA supports an module ownership. v2.0 and above. b0 - Not Supported. b1 - Ownership supported.
  [27] DBG_INDIRECT_SUP — Indicates if the HWA supports an indirect memory access port. v2.0 and above. b0 - Not Supported. b1 - Indirect port supported.
  [26] DBG_SWBP_SUP — Whether HWA Core supports SWBP or not. b0 - Not Supported. b1 - Supported.
  [25] DBQ_RESET_SUP — Whether HWA Core reset is supported or not which does not affect debug logic. b0 - Not Supported. b1 - Supported.
  [24] SYS_EXE_REQ — Whether HWA Core Execution status and control is supported. b0 - Not Supported. b1 - Supported.
  [23] TRIG_OUTPUT — b0 - Trigger Outputs are not supported. b1 - Trigger Outputs are supported.
  [22] TRIG_INPUT — b0 - Trigger Inputs are not supported. b1 - Trigger Inputs are supported.
  [21:20] TRIG_CHNS — Number of Trigger Channels Supported. b00 ------ No channels supported. b01 ------ One channel supported. b10 ------ Two channels supported. Others ---- Reserved.
  [19:16] NUM_CNTRS — The number of counter modules that exist. The registers supporting the counter modules must be implemented consecutively in the memory map.
  [15:12] NUM_WPS — The number of watchpoint modules that exist. The registers supporting the watchpoint modules must be implemented consecutively in the memory map
  [11:8] NUM_BPS — The number of breakpoint modules that exist. The registers supporting the breakpoint modules must be implemented consecutively in the memory map.
  [7:4] REV_MAJ — Major Revision
  [3:0] REV_MIN — Minor Revision
0x2658 DMPAC_TOP__CFG_SLV__HTS__S_VBUSP__REGS_dbg_cntl access not given — Debug Control register is used by debug software to control all of the basic debug functions.
  [26] DBG_RESET_OCC — Sticky status bit to reflect reset has been generated (access R/W1TC)
  [19:16] DBG_EMU0_CNTL rw — EMU0 output control. The cross trigger output control. The value in this field determines the behavior of the outputs generated on EMU0. NOTE: The effect of setting any non-zero value is ignored if the HWA Core is currently in HALTED state until the HWA core exits and re-enters HALTED state. DBG_EMUn_CNTL Output Enable Output Pulse Description 0 De-asserted 0 NA No output. Input only 1 Stopping 0 Yes Pulse on halt. If this bit is set when halted then no effect until the HWA re-enters halted state. 2 HWBP 0 Yes Pulse when any HWBP triggers 3 HWWP 0 Yes Pulse when any HWWP triggers 4 Asserted 1 No Drive pin high 5 Asserted 0 No Drive pin low 6-15 - - Reserved
  [12] DBG_HALT_EMU0 ro — Execution halted due to trigger in on EMU0 input Set to '1' when halt due to EMU0 input completes Set to '0' when execution resumes
  [11] DBG_HALT_USER ro — Execution halted due to register update of DBG_HALT Set to '1' when halt due to DBG_HALT update completes Set to '0' when execution resumes
  [10] DBG_HALT_STEP ro — Execution halted due to single step completion Set to '1' when the single step completes Set to '0' when execution resumes
  [7] DBG_EXE_STAT ro — The execution status of the module Set to '1' when halted due to debug event Set to '0' when execution resumes
  [5] DBG_EMU0_EN rw — EMU0 input trigger enable Writing '1' enables halting on the falling edge of the EMU0 input Writing '0' disables halts via EMU0 input
  [2] DBG_SINGLE_STEP_EN rw — Single Step Execution enable. When this bit is set, the accelerator core shall be halted upon execution of a single instruction. This is after the accelerator core has left the halted state by clearing the DBG_HALT control bit. Writing '1' enables halting when the next instruction following exit from halted state is executed. Writing '0' disables halts via single step. NOTE: 1. When the accelerator core enters its natural execution state, it may or may not execute an instruction and re-enter HALTED state.
  [1] DBG_RESTART rw — Debug Restart Status bit.This bit is normally set when the DBG_HALT bit transitions from '1' to '0' when the natural execution state is entered.It is a sticky bit. It may also be set when a synchronous run causes the accelerator to leave halted state. Reading '1' means HWA Core exited halted state (at least temporarily). Reading '0' means HWA Core did not exit halted state. Writing '1' shall clear the bit if set. There is no restriction on when it can be cleared. Writing '0' shall have no effect.
  [0] DBG_HALT rw — Global debug run control. The bit will be read as being set upon entry to HALTED state due to halted state being entered because of SWBP, HWBP, HWWP, EMU0 / 1 trigger or manual halt requested through this control. Writing '1' when read '0' shall cause a halt on the next possible halt boundary.Writing '0' when read '1' returns the system to the natural execution state.A synchronous run hardware request has the same effect.Reading '1' means that the halted state has been reached or been requested by the manual halt mechanism.Reading '0' means that the target is in its natural execution state.NOTE: 1. The natural execution state means the FSM state entered prior to last entry into Halted state. 2. This would be the last application requested FSM state unless the DBG_SYS_EXE_REQ control was used to change it.
